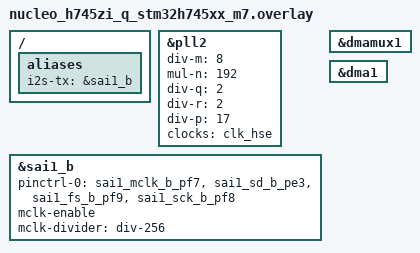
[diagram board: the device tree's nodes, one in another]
/*
 * Copyright (c) 2025 ZAL Zentrum für Angewandte Luftfahrtforschung GmbH
 * Copyright (c) 2025 Mario Paja
 *
 * SPDX-License-Identifier: Apache-2.0
 */

/ {
	aliases {
		i2s-tx = &sai1_b;
	};
};

&pll2 {
	/* 44.1KHz (0.03% Error) */
	div-m = <8>;
	mul-n = <192>;
	div-q = <2>;
	div-r = <2>;
	div-p = <17>;
	clocks = <&clk_hse>;
	status = "okay";
};

&sai1_b {
	pinctrl-0 = <&sai1_mclk_b_pf7 &sai1_sd_b_pe3
		     &sai1_fs_b_pf9 &sai1_sck_b_pf8>;
	pinctrl-names = "default";
	status = "okay";
	mclk-enable;
	mclk-divider = "div-256";
	dma-names = "tx";
};

&dmamux1 {
	status = "okay";
};

&dma1 {
	status = "okay";
};
